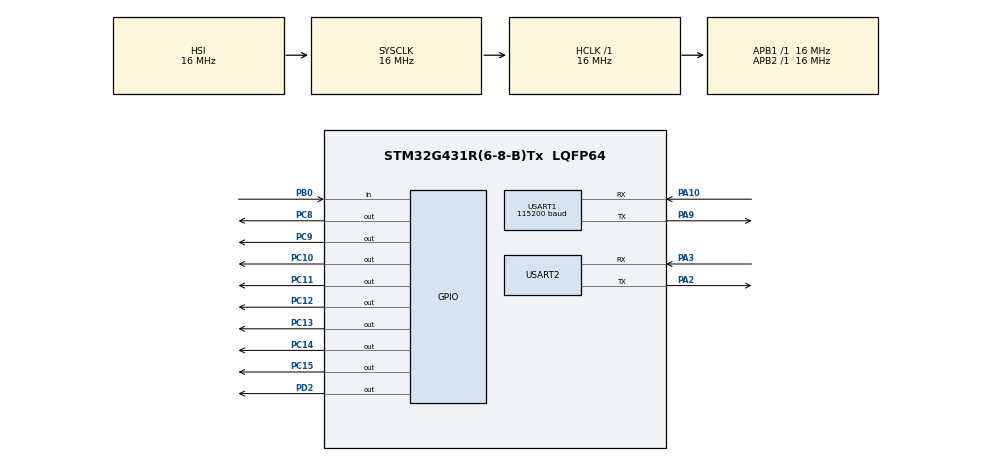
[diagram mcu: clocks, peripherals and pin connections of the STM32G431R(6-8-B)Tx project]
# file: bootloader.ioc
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Mcu.Family=STM32G4
Mcu.Name=STM32G431R(6-8-B)Tx
Mcu.Package=LQFP64
NVIC.PriorityGroup=NVIC_PRIORITYGROUP_4
NVIC.USART1_IRQn=true\:5\:0\:true\:false\:true\:true\:true\:true
NVIC.USART2_IRQn=true\:6\:0\:true\:false\:true\:true\:true\:true
PA10.Mode=Asynchronous
PA10.Signal=USART1_RX
PA13.Mode=Serial_Wire
PA13.Signal=SYS_JTMS-SWDIO
PA14.Mode=Serial_Wire
PA14.Signal=SYS_JTCK-SWCLK
PA2.Mode=Asynchronous
PA2.Signal=USART2_TX
PA3.Mode=Asynchronous
PA3.Signal=USART2_RX
PA9.Mode=Asynchronous
PA9.Signal=USART1_TX
PB0.Signal=GPIO_Input
PC10.Signal=GPIO_Output
PC11.Signal=GPIO_Output
PC12.Signal=GPIO_Output
PC13.Signal=GPIO_Output
PC14-OSC32_IN.Signal=GPIO_Output
PC15-OSC32_OUT.Signal=GPIO_Output
PC8.Signal=GPIO_Output
PC9.Signal=GPIO_Output
PD2.Signal=GPIO_Output
ProjectManager.HeapSize=0x200
ProjectManager.StackSize=0x400
ProjectManager.TargetToolchain=MDK-ARM V5.32
RCC.AHBFreq_Value=16000000
RCC.APB1Freq_Value=16000000
RCC.APB1TimFreq_Value=16000000
RCC.APB2Freq_Value=16000000
RCC.APB2TimFreq_Value=16000000
RCC.CortexFreq_Value=16000000
RCC.EXTERNAL_CLOCK_VALUE=12288000
RCC.HCLKFreq_Value=16000000
RCC.HSE_VALUE=8000000
RCC.HSI48_VALUE=48000000
RCC.HSI_VALUE=16000000
RCC.LSE_VALUE=32768
RCC.SYSCLKFreq_VALUE=16000000
RCC.USBFreq_Value=64000000
RCC.VCOOutputFreq_Value=128000000
USART1.BaudRate=115200
USART1.VirtualMode-Asynchronous=VM_ASYNC
USART2.VirtualMode-Asynchronous=VM_ASYNC
VP_SYS_VS_DBSignals.Mode=DisableDeadBatterySignals
board=custom

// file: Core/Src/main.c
/* USER CODE BEGIN Header */
/**
  ******************************************************************************
  * @file           : main.c
  * @brief          : Main program body
  ******************************************************************************
  * @attention
  *
  * Copyright (c) 2026 STMicroelectronics.
  * All rights reserved.
  *
  * This software is licensed under terms that can be found in the LICENSE file
  * in the root directory of this software component.
  * If no LICENSE file comes with this software, it is provided AS-IS.
  *
  ******************************************************************************
  */
/* USER CODE END Header */
#include "main.h"
#include "usart.h"
#include "gpio.h"

/* USER CODE BEGIN Includes */
#include "led.h"
#include "iap.h"
#include "iap_port.h"
/* USER CODE END Includes */

void SystemClock_Config(void);

int main(void)
{

  /* USER CODE BEGIN 1 */
  uint32_t blink_tick = 0;
  /* USER CODE END 1 */

  /* MCU Configuration--------------------------------------------------------*/

  /* Reset of all peripherals, Initializes the Flash interface and the Systick. */
  HAL_Init();

  /* Configure the system clock */
  SystemClock_Config();

  /* Initialize all configured peripherals */
  MX_GPIO_Init();
  MX_USART1_UART_Init();
  MX_USART2_UART_Init();
  /* USER CODE BEGIN 2 */
  led_all_off();

  if (!IAP_Port_IsButtonPressed())
    IAP_JumpToApplication();

  IAP_Init();
  IAP_Port_RxStart();
  /* USER CODE END 2 */

  /* Infinite loop */
  /* USER CODE BEGIN WHILE */

  while (1)
  {
	  IAP_Process();
	  if(HAL_GetTick() - blink_tick >= 200)
	  {
		  blink_tick = HAL_GetTick();
		  IAP_Port_LedToggle();
	  }
    /* USER CODE END WHILE */

  }
}

void SystemClock_Config(void)
{
  RCC_OscInitTypeDef RCC_OscInitStruct = {0};
  RCC_ClkInitTypeDef RCC_ClkInitStruct = {0};

  /** Configure the main internal regulator output voltage
  */
  HAL_PWREx_ControlVoltageScaling(PWR_REGULATOR_VOLTAGE_SCALE1);

  /** Initializes the RCC Oscillators according to the specified parameters
  * in the RCC_OscInitTypeDef structure.
  */
  RCC_OscInitStruct.OscillatorType = RCC_OSCILLATORTYPE_HSI;
  RCC_OscInitStruct.HSIState = RCC_HSI_ON;
  RCC_OscInitStruct.HSICalibrationValue = RCC_HSICALIBRATION_DEFAULT;
  RCC_OscInitStruct.PLL.PLLState = RCC_PLL_NONE;
  if (HAL_RCC_OscConfig(&RCC_OscInitStruct) != HAL_OK)
  {
    Error_Handler();
  }

  /** Initializes the CPU, AHB and APB buses clocks
  */
  RCC_ClkInitStruct.ClockType = RCC_CLOCKTYPE_HCLK|RCC_CLOCKTYPE_SYSCLK
                              |RCC_CLOCKTYPE_PCLK1|RCC_CLOCKTYPE_PCLK2;
  RCC_ClkInitStruct.SYSCLKSource = RCC_SYSCLKSOURCE_HSI;
  RCC_ClkInitStruct.AHBCLKDivider = RCC_SYSCLK_DIV1;
  RCC_ClkInitStruct.APB1CLKDivider = RCC_HCLK_DIV1;
  RCC_ClkInitStruct.APB2CLKDivider = RCC_HCLK_DIV1;

  if (HAL_RCC_ClockConfig(&RCC_ClkInitStruct, FLASH_LATENCY_0) != HAL_OK)
  {
    Error_Handler();
  }
}

void Error_Handler(void)
{
  __disable_irq();
  while (1)
  {
  }
}
